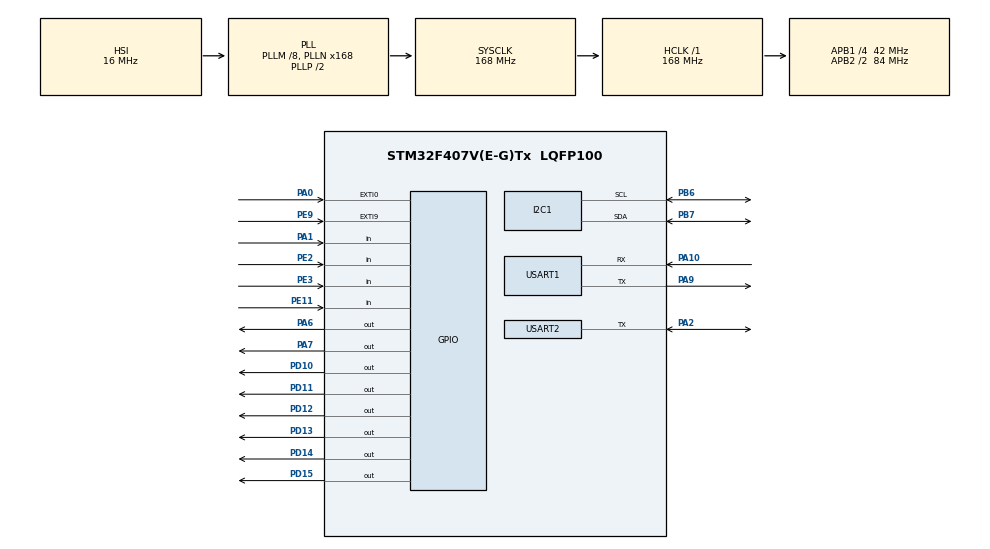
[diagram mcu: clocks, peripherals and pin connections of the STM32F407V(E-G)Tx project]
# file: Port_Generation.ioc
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Mcu.Family=STM32F4
VP_TIM5_VS_ClockSourceINT.Mode=Internal
RCC.CortexFreq_Value=168000000
RCC.SYSCLKSource=RCC_SYSCLKSOURCE_PLLCLK
ProjectManager.StackSize=0x400
PD13.Signal=GPIO_Output
PE11.GPIO_PuPd=GPIO_PULLUP
RCC.HCLKFreq_Value=168000000
RCC.APB2TimFreq_Value=168000000
PB6.Signal=I2C1_SCL
PB6.Mode=I2C
PA1.GPIO_PuPd=GPIO_PULLUP
RCC.AHBFreq_Value=168000000
RCC.HSE_VALUE=25000000
PB3.Mode=JTAG_5_pins
VP_TIM4_VS_no_output1.Mode=Output Compare1 No Output
PA15.Mode=JTAG_5_pins
TIM8.Channel-Output\ Compare1\ No\ Output=TIM_CHANNEL_1
PB4.Mode=JTAG_5_pins
PE9.Signal=GPXTI9
PA14.Mode=JTAG_5_pins
PE2.Signal=GPIO_Input
PB7.Signal=I2C1_SDA
Mcu.Package=LQFP100
PA6.Signal=GPIO_Output
USART2.VirtualMode=VM_ASYNC
PD12.Signal=GPIO_Output
PA10.Signal=USART1_RX
PA15.Signal=SYS_JTDI
RCC.APB2CLKDivider=RCC_HCLK_DIV2
RCC.APB1TimFreq_Value=84000000
NVIC.USART1_IRQn=true\:0\:0\:false\:false\:true\:true\:true
PD15.Signal=GPIO_Output
VP_TIM3_VS_ClockSourceINT.Mode=Internal
TIM4.Channel-Output\ Compare1\ No\ Output=TIM_CHANNEL_1
PB4.Signal=SYS_JTRST
TIM3.Channel-Output\ Compare1\ No\ Output=TIM_CHANNEL_1
PA10.Mode=Asynchronous
RCC.APB1CLKDivider=RCC_HCLK_DIV4
PA0-WKUP.Signal=GPXTI0
TIM5.Channel-Output\ Compare1\ No\ Output=TIM_CHANNEL_1
PD10.Signal=GPIO_Output
PA13.Signal=SYS_JTMS-SWDIO
PA9.Mode=Asynchronous
ProjectManager.TargetToolchain=TrueSTUDIO
PA9.Signal=USART1_TX
VP_TIM8_VS_ClockSourceINT.Mode=Internal
PE11.Signal=GPIO_Input
RCC.LSE_VALUE=32768
PA1.Signal=GPIO_Input
VP_TIM8_VS_no_output1.Mode=Output Compare1 No Output
VP_TIM5_VS_no_output1.Mode=Output Compare1 No Output
board=custom
VP_TIM3_VS_no_output1.Mode=Output Compare1 No Output
RCC.VCOOutputFreq_Value=336000000
RCC.APB2Freq_Value=84000000
PA13.Mode=JTAG_5_pins
Mcu.Name=STM32F407V(E-G)Tx
PA2.Signal=USART2_TX
PD14.Signal=GPIO_Output
RCC.48MHZClocksFreq_Value=84000000
PB3.Signal=SYS_JTDO-SWO
NVIC.EXTI0_IRQn=true\:0\:0\:false\:false\:true\:true\:true
RCC.SYSCLKFreq_VALUE=168000000
PD11.Signal=GPIO_Output
USART1.VirtualMode=VM_ASYNC
PB7.Mode=I2C
NVIC.EXTI9_5_IRQn=true\:0\:0\:false\:false\:true\:true\:true
PA14.Signal=SYS_JTCK-SWCLK
ProjectManager.HeapSize=0x200
RCC.HSI_VALUE=16000000
VP_TIM4_VS_ClockSourceINT.Mode=Internal
NVIC.PriorityGroup=NVIC_PRIORITYGROUP_4
RCC.PLLM=8
RCC.PLLN=168
PA2.Mode=Half_duplex(single_wire_mode)
PE3.Signal=GPIO_Input
PA0-WKUP.GPIO_PuPd=GPIO_PULLUP
RCC.APB1Freq_Value=42000000
PA7.Signal=GPIO_Output
PE9.GPIO_PuPd=GPIO_PULLUP

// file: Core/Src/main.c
/* USER CODE BEGIN Header */
/**
  ******************************************************************************
  * @file           : main.c
  * @brief          : Main program body
  ******************************************************************************
  * @attention
  *
  * <h2><center>&copy; Copyright (c) 2020 STMicroelectronics.
  * All rights reserved.</center></h2>
  *
  * This software component is licensed by ST under BSD 3-Clause license,
  * the "License"; You may not use this file except in compliance with the
  * License. You may obtain a copy of the License at:
  *                        opensource.org/licenses/BSD-3-Clause
  *
  ******************************************************************************
  */
/* USER CODE END Header */
#include "main.h"

I2C_HandleTypeDef hi2c1;

TIM_HandleTypeDef htim3;
TIM_HandleTypeDef htim4;
TIM_HandleTypeDef htim5;
TIM_HandleTypeDef htim8;

UART_HandleTypeDef huart1;
UART_HandleTypeDef huart2;

void SystemClock_Config(void);
static void MX_GPIO_Init(void);
static void MX_I2C1_Init(void);
static void MX_TIM3_Init(void);
static void MX_TIM4_Init(void);
static void MX_TIM5_Init(void);
static void MX_TIM8_Init(void);
static void MX_USART1_UART_Init(void);
static void MX_USART2_UART_Init(void);

int main(void)
{
  /* USER CODE BEGIN 1 */
	const char test[10] = "Hello\r\n";
  /* USER CODE END 1 */

  /* MCU Configuration--------------------------------------------------------*/

  /* Reset of all peripherals, Initializes the Flash interface and the Systick. */
  HAL_Init();

  /* Configure the system clock */
  SystemClock_Config();

  /* Initialize all configured peripherals */
  MX_GPIO_Init();
  MX_I2C1_Init();
  MX_TIM3_Init();
  MX_TIM4_Init();
  MX_TIM5_Init();
  MX_TIM8_Init();
  MX_USART1_UART_Init();
  MX_USART2_UART_Init();

  /* Infinite loop */
  while (1)
  {
	  HAL_UART_Transmit(&huart1, (uint8_t*)test, 7, 10);
  }
}

void SystemClock_Config(void)
{
  RCC_OscInitTypeDef RCC_OscInitStruct = {0};
  RCC_ClkInitTypeDef RCC_ClkInitStruct = {0};

  /** Configure the main internal regulator output voltage
  */
  __HAL_RCC_PWR_CLK_ENABLE();
  __HAL_PWR_VOLTAGESCALING_CONFIG(PWR_REGULATOR_VOLTAGE_SCALE1);
  /** Initializes the RCC Oscillators according to the specified parameters
  * in the RCC_OscInitTypeDef structure.
  */
  RCC_OscInitStruct.OscillatorType = RCC_OSCILLATORTYPE_HSI;
  RCC_OscInitStruct.HSIState = RCC_HSI_ON;
  RCC_OscInitStruct.HSICalibrationValue = RCC_HSICALIBRATION_DEFAULT;
  RCC_OscInitStruct.PLL.PLLState = RCC_PLL_ON;
  RCC_OscInitStruct.PLL.PLLSource = RCC_PLLSOURCE_HSI;
  RCC_OscInitStruct.PLL.PLLM = 8;
  RCC_OscInitStruct.PLL.PLLN = 168;
  RCC_OscInitStruct.PLL.PLLP = RCC_PLLP_DIV2;
  RCC_OscInitStruct.PLL.PLLQ = 4;
  if (HAL_RCC_OscConfig(&RCC_OscInitStruct) != HAL_OK)
  {
    Error_Handler();
  }
  /** Initializes the CPU, AHB and APB buses clocks
  */
  RCC_ClkInitStruct.ClockType = RCC_CLOCKTYPE_HCLK|RCC_CLOCKTYPE_SYSCLK
                              |RCC_CLOCKTYPE_PCLK1|RCC_CLOCKTYPE_PCLK2;
  RCC_ClkInitStruct.SYSCLKSource = RCC_SYSCLKSOURCE_PLLCLK;
  RCC_ClkInitStruct.AHBCLKDivider = RCC_SYSCLK_DIV1;
  RCC_ClkInitStruct.APB1CLKDivider = RCC_HCLK_DIV4;
  RCC_ClkInitStruct.APB2CLKDivider = RCC_HCLK_DIV2;

  if (HAL_RCC_ClockConfig(&RCC_ClkInitStruct, FLASH_LATENCY_5) != HAL_OK)
  {
    Error_Handler();
  }
}

static void MX_I2C1_Init(void)
{

  hi2c1.Instance = I2C1;
  hi2c1.Init.ClockSpeed = 100000;
  hi2c1.Init.DutyCycle = I2C_DUTYCYCLE_2;
  hi2c1.Init.OwnAddress1 = 0;
  hi2c1.Init.AddressingMode = I2C_ADDRESSINGMODE_7BIT;
  hi2c1.Init.DualAddressMode = I2C_DUALADDRESS_DISABLE;
  hi2c1.Init.OwnAddress2 = 0;
  hi2c1.Init.GeneralCallMode = I2C_GENERALCALL_DISABLE;
  hi2c1.Init.NoStretchMode = I2C_NOSTRETCH_DISABLE;
  if (HAL_I2C_Init(&hi2c1) != HAL_OK)
  {
    Error_Handler();
  }

}

static void MX_TIM3_Init(void)
{

  TIM_ClockConfigTypeDef sClockSourceConfig = {0};
  TIM_MasterConfigTypeDef sMasterConfig = {0};
  TIM_OC_InitTypeDef sConfigOC = {0};

  htim3.Instance = TIM3;
  htim3.Init.Prescaler = 0;
  htim3.Init.CounterMode = TIM_COUNTERMODE_UP;
  htim3.Init.Period = 65535;
  htim3.Init.ClockDivision = TIM_CLOCKDIVISION_DIV1;
  htim3.Init.AutoReloadPreload = TIM_AUTORELOAD_PRELOAD_DISABLE;
  if (HAL_TIM_Base_Init(&htim3) != HAL_OK)
  {
    Error_Handler();
  }
  sClockSourceConfig.ClockSource = TIM_CLOCKSOURCE_INTERNAL;
  if (HAL_TIM_ConfigClockSource(&htim3, &sClockSourceConfig) != HAL_OK)
  {
    Error_Handler();
  }
  if (HAL_TIM_OC_Init(&htim3) != HAL_OK)
  {
    Error_Handler();
  }
  sMasterConfig.MasterOutputTrigger = TIM_TRGO_RESET;
  sMasterConfig.MasterSlaveMode = TIM_MASTERSLAVEMODE_DISABLE;
  if (HAL_TIMEx_MasterConfigSynchronization(&htim3, &sMasterConfig) != HAL_OK)
  {
    Error_Handler();
  }
  sConfigOC.OCMode = TIM_OCMODE_TIMING;
  sConfigOC.Pulse = 0;
  sConfigOC.OCPolarity = TIM_OCPOLARITY_HIGH;
  sConfigOC.OCFastMode = TIM_OCFAST_DISABLE;
  if (HAL_TIM_OC_ConfigChannel(&htim3, &sConfigOC, TIM_CHANNEL_1) != HAL_OK)
  {
    Error_Handler();
  }

}

static void MX_TIM4_Init(void)
{

  TIM_ClockConfigTypeDef sClockSourceConfig = {0};
  TIM_MasterConfigTypeDef sMasterConfig = {0};
  TIM_OC_InitTypeDef sConfigOC = {0};

  htim4.Instance = TIM4;
  htim4.Init.Prescaler = 0;
  htim4.Init.CounterMode = TIM_COUNTERMODE_UP;
  htim4.Init.Period = 65535;
  htim4.Init.ClockDivision = TIM_CLOCKDIVISION_DIV1;
  htim4.Init.AutoReloadPreload = TIM_AUTORELOAD_PRELOAD_DISABLE;
  if (HAL_TIM_Base_Init(&htim4) != HAL_OK)
  {
    Error_Handler();
  }
  sClockSourceConfig.ClockSource = TIM_CLOCKSOURCE_INTERNAL;
  if (HAL_TIM_ConfigClockSource(&htim4, &sClockSourceConfig) != HAL_OK)
  {
    Error_Handler();
  }
  if (HAL_TIM_OC_Init(&htim4) != HAL_OK)
  {
    Error_Handler();
  }
  sMasterConfig.MasterOutputTrigger = TIM_TRGO_RESET;
  sMasterConfig.MasterSlaveMode = TIM_MASTERSLAVEMODE_DISABLE;
  if (HAL_TIMEx_MasterConfigSynchronization(&htim4, &sMasterConfig) != HAL_OK)
  {
    Error_Handler();
  }
  sConfigOC.OCMode = TIM_OCMODE_TIMING;
  sConfigOC.Pulse = 0;
  sConfigOC.OCPolarity = TIM_OCPOLARITY_HIGH;
  sConfigOC.OCFastMode = TIM_OCFAST_DISABLE;
  if (HAL_TIM_OC_ConfigChannel(&htim4, &sConfigOC, TIM_CHANNEL_1) != HAL_OK)
  {
    Error_Handler();
  }

}

static void MX_TIM5_Init(void)
{

  TIM_ClockConfigTypeDef sClockSourceConfig = {0};
  TIM_MasterConfigTypeDef sMasterConfig = {0};
  TIM_OC_InitTypeDef sConfigOC = {0};

  htim5.Instance = TIM5;
  htim5.Init.Prescaler = 0;
  htim5.Init.CounterMode = TIM_COUNTERMODE_UP;
  htim5.Init.Period = 4294967295;
  htim5.Init.ClockDivision = TIM_CLOCKDIVISION_DIV1;
  htim5.Init.AutoReloadPreload = TIM_AUTORELOAD_PRELOAD_DISABLE;
  if (HAL_TIM_Base_Init(&htim5) != HAL_OK)
  {
    Error_Handler();
  }
  sClockSourceConfig.ClockSource = TIM_CLOCKSOURCE_INTERNAL;
  if (HAL_TIM_ConfigClockSource(&htim5, &sClockSourceConfig) != HAL_OK)
  {
    Error_Handler();
  }
  if (HAL_TIM_OC_Init(&htim5) != HAL_OK)
  {
    Error_Handler();
  }
  sMasterConfig.MasterOutputTrigger = TIM_TRGO_RESET;
  sMasterConfig.MasterSlaveMode = TIM_MASTERSLAVEMODE_DISABLE;
  if (HAL_TIMEx_MasterConfigSynchronization(&htim5, &sMasterConfig) != HAL_OK)
  {
    Error_Handler();
  }
  sConfigOC.OCMode = TIM_OCMODE_TIMING;
  sConfigOC.Pulse = 0;
  sConfigOC.OCPolarity = TIM_OCPOLARITY_HIGH;
  sConfigOC.OCFastMode = TIM_OCFAST_DISABLE;
  if (HAL_TIM_OC_ConfigChannel(&htim5, &sConfigOC, TIM_CHANNEL_1) != HAL_OK)
  {
    Error_Handler();
  }

}

static void MX_TIM8_Init(void)
{

  TIM_ClockConfigTypeDef sClockSourceConfig = {0};
  TIM_MasterConfigTypeDef sMasterConfig = {0};
  TIM_OC_InitTypeDef sConfigOC = {0};
  TIM_BreakDeadTimeConfigTypeDef sBreakDeadTimeConfig = {0};

  htim8.Instance = TIM8;
  htim8.Init.Prescaler = 0;
  htim8.Init.CounterMode = TIM_COUNTERMODE_UP;
  htim8.Init.Period = 65535;
  htim8.Init.ClockDivision = TIM_CLOCKDIVISION_DIV1;
  htim8.Init.RepetitionCounter = 0;
  htim8.Init.AutoReloadPreload = TIM_AUTORELOAD_PRELOAD_DISABLE;
  if (HAL_TIM_Base_Init(&htim8) != HAL_OK)
  {
    Error_Handler();
  }
  sClockSourceConfig.ClockSource = TIM_CLOCKSOURCE_INTERNAL;
  if (HAL_TIM_ConfigClockSource(&htim8, &sClockSourceConfig) != HAL_OK)
  {
    Error_Handler();
  }
  if (HAL_TIM_OC_Init(&htim8) != HAL_OK)
  {
    Error_Handler();
  }
  sMasterConfig.MasterOutputTrigger = TIM_TRGO_RESET;
  sMasterConfig.MasterSlaveMode = TIM_MASTERSLAVEMODE_DISABLE;
  if (HAL_TIMEx_MasterConfigSynchronization(&htim8, &sMasterConfig) != HAL_OK)
  {
    Error_Handler();
  }
  sConfigOC.OCMode = TIM_OCMODE_TIMING;
  sConfigOC.Pulse = 0;
  sConfigOC.OCPolarity = TIM_OCPOLARITY_HIGH;
  sConfigOC.OCNPolarity = TIM_OCNPOLARITY_HIGH;
  sConfigOC.OCFastMode = TIM_OCFAST_DISABLE;
  sConfigOC.OCIdleState = TIM_OCIDLESTATE_RESET;
  sConfigOC.OCNIdleState = TIM_OCNIDLESTATE_RESET;
  if (HAL_TIM_OC_ConfigChannel(&htim8, &sConfigOC, TIM_CHANNEL_1) != HAL_OK)
  {
    Error_Handler();
  }
  sBreakDeadTimeConfig.OffStateRunMode = TIM_OSSR_DISABLE;
  sBreakDeadTimeConfig.OffStateIDLEMode = TIM_OSSI_DISABLE;
  sBreakDeadTimeConfig.LockLevel = TIM_LOCKLEVEL_OFF;
  sBreakDeadTimeConfig.DeadTime = 0;
  sBreakDeadTimeConfig.BreakState = TIM_BREAK_DISABLE;
  sBreakDeadTimeConfig.BreakPolarity = TIM_BREAKPOLARITY_HIGH;
  sBreakDeadTimeConfig.AutomaticOutput = TIM_AUTOMATICOUTPUT_DISABLE;
  if (HAL_TIMEx_ConfigBreakDeadTime(&htim8, &sBreakDeadTimeConfig) != HAL_OK)
  {
    Error_Handler();
  }

}

static void MX_USART1_UART_Init(void)
{

  huart1.Instance = USART1;
  huart1.Init.BaudRate = 115200;
  huart1.Init.WordLength = UART_WORDLENGTH_8B;
  huart1.Init.StopBits = UART_STOPBITS_1;
  huart1.Init.Parity = UART_PARITY_NONE;
  huart1.Init.Mode = UART_MODE_TX_RX;
  huart1.Init.HwFlowCtl = UART_HWCONTROL_NONE;
  huart1.Init.OverSampling = UART_OVERSAMPLING_16;
  if (HAL_UART_Init(&huart1) != HAL_OK)
  {
    Error_Handler();
  }

}

static void MX_USART2_UART_Init(void)
{

  huart2.Instance = USART2;
  huart2.Init.BaudRate = 115200;
  huart2.Init.WordLength = UART_WORDLENGTH_8B;
  huart2.Init.StopBits = UART_STOPBITS_1;
  huart2.Init.Parity = UART_PARITY_NONE;
  huart2.Init.Mode = UART_MODE_TX_RX;
  huart2.Init.HwFlowCtl = UART_HWCONTROL_NONE;
  huart2.Init.OverSampling = UART_OVERSAMPLING_16;
  if (HAL_HalfDuplex_Init(&huart2) != HAL_OK)
  {
    Error_Handler();
  }

}

static void MX_GPIO_Init(void)
{
  GPIO_InitTypeDef GPIO_InitStruct = {0};

  /* GPIO Ports Clock Enable */
  __HAL_RCC_GPIOE_CLK_ENABLE();
  __HAL_RCC_GPIOA_CLK_ENABLE();
  __HAL_RCC_GPIOD_CLK_ENABLE();
  __HAL_RCC_GPIOB_CLK_ENABLE();

  /*Configure GPIO pin Output Level */
  HAL_GPIO_WritePin(GPIOA, GPIO_PIN_6|GPIO_PIN_7, GPIO_PIN_RESET);

  /*Configure GPIO pin Output Level */
  HAL_GPIO_WritePin(GPIOD, GPIO_PIN_10|GPIO_PIN_11|GPIO_PIN_12|GPIO_PIN_13
                          |GPIO_PIN_14|GPIO_PIN_15, GPIO_PIN_RESET);

  /*Configure GPIO pins : PE2 PE3 */
  GPIO_InitStruct.Pin = GPIO_PIN_2|GPIO_PIN_3;
  GPIO_InitStruct.Mode = GPIO_MODE_INPUT;
  GPIO_InitStruct.Pull = GPIO_NOPULL;
  HAL_GPIO_Init(GPIOE, &GPIO_InitStruct);

  /*Configure GPIO pin : PA0 */
  GPIO_InitStruct.Pin = GPIO_PIN_0;
  GPIO_InitStruct.Mode = GPIO_MODE_IT_RISING;
  GPIO_InitStruct.Pull = GPIO_PULLUP;
  HAL_GPIO_Init(GPIOA, &GPIO_InitStruct);

  /*Configure GPIO pin : PA1 */
  GPIO_InitStruct.Pin = GPIO_PIN_1;
  GPIO_InitStruct.Mode = GPIO_MODE_INPUT;
  GPIO_InitStruct.Pull = GPIO_PULLUP;
  HAL_GPIO_Init(GPIOA, &GPIO_InitStruct);

  /*Configure GPIO pins : PA6 PA7 */
  GPIO_InitStruct.Pin = GPIO_PIN_6|GPIO_PIN_7;
  GPIO_InitStruct.Mode = GPIO_MODE_OUTPUT_PP;
  GPIO_InitStruct.Pull = GPIO_NOPULL;
  GPIO_InitStruct.Speed = GPIO_SPEED_FREQ_LOW;
  HAL_GPIO_Init(GPIOA, &GPIO_InitStruct);

  /*Configure GPIO pin : PE9 */
  GPIO_InitStruct.Pin = GPIO_PIN_9;
  GPIO_InitStruct.Mode = GPIO_MODE_IT_RISING;
  GPIO_InitStruct.Pull = GPIO_PULLUP;
  HAL_GPIO_Init(GPIOE, &GPIO_InitStruct);

  /*Configure GPIO pin : PE11 */
  GPIO_InitStruct.Pin = GPIO_PIN_11;
  GPIO_InitStruct.Mode = GPIO_MODE_INPUT;
  GPIO_InitStruct.Pull = GPIO_PULLUP;
  HAL_GPIO_Init(GPIOE, &GPIO_InitStruct);

  /*Configure GPIO pins : PD10 PD11 PD12 PD13
                           PD14 PD15 */
  GPIO_InitStruct.Pin = GPIO_PIN_10|GPIO_PIN_11|GPIO_PIN_12|GPIO_PIN_13
                          |GPIO_PIN_14|GPIO_PIN_15;
  GPIO_InitStruct.Mode = GPIO_MODE_OUTPUT_PP;
  GPIO_InitStruct.Pull = GPIO_NOPULL;
  GPIO_InitStruct.Speed = GPIO_SPEED_FREQ_LOW;
  HAL_GPIO_Init(GPIOD, &GPIO_InitStruct);

  /* EXTI interrupt init*/
  HAL_NVIC_SetPriority(EXTI0_IRQn, 0, 0);
  HAL_NVIC_EnableIRQ(EXTI0_IRQn);

  HAL_NVIC_SetPriority(EXTI9_5_IRQn, 0, 0);
  HAL_NVIC_EnableIRQ(EXTI9_5_IRQn);

}

void Error_Handler(void)
{
}

/************************ (C) COPYRIGHT STMicroelectronics *****END OF FILE****/
